VERSION ""

NS_ :

BS_:

BU_: ECM BCM Cluster
VAL_TABLE_ Seta_E_D 3 "Alerta" 2 "Direita" 1 "Esquerda" 0 "Desligado" ;
VAL_TABLE_ Freio 1 "Acionado" 0 "Nao Acionado" ;
VAL_TABLE_ Porta 1 "Aberta" 0 "Fechada" ;
VAL_TABLE_ Farol 4 "Erro" 3 "Farol Alto" 2 "Farol Medio" 1 "Farol Baixo" 0 "Desligado" ;

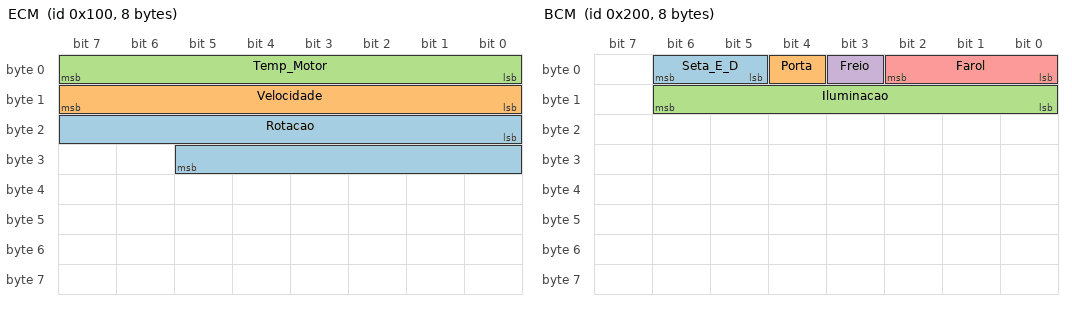
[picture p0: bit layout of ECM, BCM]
BO_ 256 ECM: 8 ECM
 SG_ Rotacao : 16|14@1+ (1,0) [0|10000] "rpm"  Cluster
 SG_ Velocidade : 8|8@1+ (1,0) [0|255] "Km/h"  Cluster
 SG_ Temp_Motor : 0|8@1+ (1,0) [0|150] "C"  Cluster

BO_ 512 BCM: 8 BCM
 SG_ Seta_E_D : 5|2@1+ (1,0) [0|3] ""  Cluster
 SG_ Porta : 4|1@1+ (1,0) [0|1] ""  Cluster
 SG_ Iluminacao : 8|7@1+ (1,0) [0|100] "%"  Cluster
 SG_ Freio : 3|1@1+ (1,0) [0|1] ""  Cluster
 SG_ Farol : 0|3@1+ (1,0) [0|4] ""  Cluster

BO_ 768 CruiseControl: 8 Cluster
 SG_ Velocidade_Cruise : 0|8@1+ (1,0) [0|255] "Km/h"  ECM
 SG_ Cruise_Ativo : 8|1@1+ (1,0) [0|1] ""  ECM

BA_DEF_  "BusType" STRING ;
BA_DEF_DEF_  "BusType" "CAN";
VAL_ 512 Seta_E_D 3 "Alerta" 2 "Direita" 1 "Esquerda" 0 "Desligado" ;
VAL_ 512 Porta 1 "Aberta" 0 "Fechada" ;
VAL_ 512 Freio 1 "Acionado" 0 "Nao Acionado" ;
VAL_ 512 Farol 4 "Erro" 3 "Farol Alto" 2 "Farol Medio" 1 "Farol Baixo" 0 "Desligado" ;
